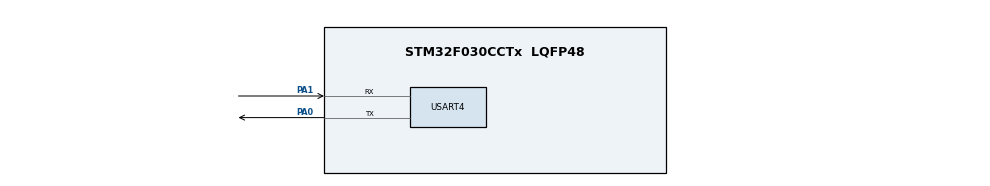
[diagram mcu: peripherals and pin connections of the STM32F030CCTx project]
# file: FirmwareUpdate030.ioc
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Mcu.Family=STM32F0
Mcu.Name=STM32F030CCTx
Mcu.Package=LQFP48
NVIC.USART3_6_IRQn=true\:0\:0\:false\:false\:true
PA0.Mode=Asynchronous
PA0.Signal=USART4_TX
PA1.Mode=Asynchronous
PA1.Signal=USART4_RX
PF0-OSC_IN.Mode=HSE-External-Oscillator
PF0-OSC_IN.Signal=RCC_OSC_IN
PF1-OSC_OUT.Mode=HSE-External-Oscillator
PF1-OSC_OUT.Signal=RCC_OSC_OUT
ProjectManager.HeapSize=0x200
ProjectManager.StackSize=0x400
ProjectManager.TargetToolchain=MDK-ARM V5
RCC.AHBFreq_Value=48000000
RCC.APB1Freq_Value=48000000
RCC.APB1TimFreq_Value=48000000
RCC.HCLKFreq_Value=48000000
RCC.PLLMUL=RCC_PLL_MUL6
RCC.SYSCLKFreq_VALUE=48000000
RCC.SYSCLKSource=RCC_SYSCLKSOURCE_PLLCLK
USART4.VirtualMode-Asynchronous=VM_ASYNC
USART4.WordLength=WORDLENGTH_8B
board=FirmwareUpdate030

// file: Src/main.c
/**
  ******************************************************************************
  * File Name          : main.c
  * Description        : Main program body
  ******************************************************************************
  ** This notice applies to any and all portions of this file
  * that are not between comment pairs USER CODE BEGIN and
  * USER CODE END. Other portions of this file, whether
  * inserted by the user or by software development tools
  * are owned by their respective copyright owners.
  *
  * COPYRIGHT(c) 2017 STMicroelectronics
  *
  * Redistribution and use in source and binary forms, with or without modification,
  * are permitted provided that the following conditions are met:
  *   1. Redistributions of source code must retain the above copyright notice,
  *      this list of conditions and the following disclaimer.
  *   2. Redistributions in binary form must reproduce the above copyright notice,
  *      this list of conditions and the following disclaimer in the documentation
  *      and/or other materials provided with the distribution.
  *   3. Neither the name of STMicroelectronics nor the names of its contributors
  *      may be used to endorse or promote products derived from this software
  *      without specific prior written permission.
  *
  * THIS SOFTWARE IS PROVIDED BY THE COPYRIGHT HOLDERS AND CONTRIBUTORS "AS IS"
  * AND ANY EXPRESS OR IMPLIED WARRANTIES, INCLUDING, BUT NOT LIMITED TO, THE
  * IMPLIED WARRANTIES OF MERCHANTABILITY AND FITNESS FOR A PARTICULAR PURPOSE ARE
  * DISCLAIMED. IN NO EVENT SHALL THE COPYRIGHT HOLDER OR CONTRIBUTORS BE LIABLE
  * FOR ANY DIRECT, INDIRECT, INCIDENTAL, SPECIAL, EXEMPLARY, OR CONSEQUENTIAL
  * DAMAGES (INCLUDING, BUT NOT LIMITED TO, PROCUREMENT OF SUBSTITUTE GOODS OR
  * SERVICES; LOSS OF USE, DATA, OR PROFITS; OR BUSINESS INTERRUPTION) HOWEVER
  * CAUSED AND ON ANY THEORY OF LIABILITY, WHETHER IN CONTRACT, STRICT LIABILITY,
  * OR TORT (INCLUDING NEGLIGENCE OR OTHERWISE) ARISING IN ANY WAY OUT OF THE USE
  * OF THIS SOFTWARE, EVEN IF ADVISED OF THE POSSIBILITY OF SUCH DAMAGE.
  *
  ******************************************************************************
  */
#include "main.h"
#include "usart.h"
#include "gpio.h"

/* USER CODE BEGIN Includes */

#include "FirmwareUpdate.h"
/* USER CODE END Includes */

/* USER CODE BEGIN PV */
/* Private variables ---------------------------------------------------------*/

/* USER CODE END PV */

static void LL_Init(void);
void SystemClock_Config(void);

/* USER CODE BEGIN PFP */
/* Private function prototypes -----------------------------------------------*/

/* USER CODE END PFP */

int main(void)
{

  /* MCU Configuration----------------------------------------------------------*/

  /* Reset of all peripherals, Initializes the Flash interface and the Systick. */
  LL_Init();

  /* Configure the system clock */
  SystemClock_Config();

  /* USER CODE BEGIN SysInit */
	goto Init;
  /* USER CODE END SysInit */

  /* Initialize all configured peripherals */
  MX_GPIO_Init();
  MX_USART4_UART_Init();

  /* USER CODE BEGIN 2 */
	Init:
	FirmwareUpdate_Init();
	FirmwareUpdate_Run();
  /* USER CODE END 2 */

  /* Infinite loop */
  while (1)
  {

  }

}

static void LL_Init(void)
{

  LL_APB1_GRP2_EnableClock(LL_APB1_GRP2_PERIPH_SYSCFG);

  /* System interrupt init*/
  /* SVC_IRQn interrupt configuration */
  NVIC_SetPriority(SVC_IRQn, 0);
  /* PendSV_IRQn interrupt configuration */
  NVIC_SetPriority(PendSV_IRQn, 0);
  /* SysTick_IRQn interrupt configuration */
  NVIC_SetPriority(SysTick_IRQn, 0);

}

/** System Clock Configuration
*/
void SystemClock_Config(void)
{

  LL_FLASH_SetLatency(LL_FLASH_LATENCY_1);

  if(LL_FLASH_GetLatency() != LL_FLASH_LATENCY_1)
  {
  Error_Handler();
  }
  LL_RCC_HSI_Enable();

   /* Wait till HSI is ready */
  while(LL_RCC_HSI_IsReady() != 1)
  {

  }
  LL_RCC_HSI_SetCalibTrimming(16);

  LL_RCC_PLL_ConfigDomain_SYS(LL_RCC_PLLSOURCE_HSI, LL_RCC_PLL_MUL_6, LL_RCC_PREDIV_DIV_1);

  LL_RCC_PLL_Enable();

   /* Wait till PLL is ready */
  while(LL_RCC_PLL_IsReady() != 1)
  {

  }
  LL_RCC_SetAHBPrescaler(LL_RCC_SYSCLK_DIV_1);

  LL_RCC_SetAPB1Prescaler(LL_RCC_APB1_DIV_1);

  LL_RCC_SetSysClkSource(LL_RCC_SYS_CLKSOURCE_PLL);

   /* Wait till System clock is ready */
  while(LL_RCC_GetSysClkSource() != LL_RCC_SYS_CLKSOURCE_STATUS_PLL)
  {

  }
  LL_Init1msTick(48000000);

  LL_SYSTICK_SetClkSource(LL_SYSTICK_CLKSOURCE_HCLK);

  LL_SetSystemCoreClock(48000000);

  /* SysTick_IRQn interrupt configuration */
  NVIC_SetPriority(SysTick_IRQn, 0);
}

void _Error_Handler(char * file, int line)
{
  while(1)
  {
  }
}

/************************ (C) COPYRIGHT STMicroelectronics *****END OF FILE****/
